VERSION ""

NS_ :

BS_:

BU_: Tank_Sensor2
VAL_TABLE_ FMS_PushButtonStates 1 "On" 0 "Off" ;
VAL_TABLE_ FMS_SSM 3 "Failure Warning " 2 "Functional Test" 1 "NCD" 0 "Normal Operation " ;
VAL_TABLE_ FMS_SDI 2 "Computer 2" 1 "Computer 1" ;
VAL_TABLE_ FMS_Pump_States 1 "Off" 0 "Energized" ;
VAL_TABLE_ vt_BNRaccuracy 1 "Degraded Accuracy" 0 "Nominal Accuracy" ;
VAL_TABLE_ vt_BCDstatus_above_below 3 "Below" 2 "FT (functional test)" 1 "NCD (no computed data)" 0 "Above" ;
VAL_TABLE_ vt_BCDstatus_to_from 3 "From" 2 "FT (functional test)" 1 "NCD (no computed data)" 0 "To" ;
VAL_TABLE_ vt_BCDstatus_right_left 3 "Left" 2 "FT (functional test)" 1 "NCD (no computed data)" 0 "Right" ;
VAL_TABLE_ vt_BCDstatus_east_west 3 "West" 2 "FT (functional test)" 1 "NCD (no computed data)" 0 "East" ;
VAL_TABLE_ vt_BCDstatus_north_south 3 "South" 2 "FT (functional test)" 1 "NCD (no computed data)" 0 "North" ;
VAL_TABLE_ vt_BCDstatus_plus_minus 3 "Minus" 2 "FT (functional test)" 1 "NCD (no computed data)" 0 "Plus" ;
VAL_TABLE_ vt_DSCstatus 3 "FW (failure warning)" 2 "FT (functional test)" 1 "NCD (no computed data)" 0 "NO (normal operation)" ;
VAL_TABLE_ vt_BNRsign_above_below 1 "Below" 0 "Above" ;
VAL_TABLE_ vt_BNRsign_to_from 1 "From" 0 "To" ;
VAL_TABLE_ vt_BNRsign_right_left 1 "Left" 0 "Right" ;
VAL_TABLE_ vt_BNRsign_east_west 1 "West" 0 "East" ;
VAL_TABLE_ vt_BNRsign_north_south 1 "South" 0 "North" ;
VAL_TABLE_ vt_BNRsign_plus_minus 1 "Minus" 0 "Plus" ;
VAL_TABLE_ vt_BNRstatus 3 "NO (normal operation)" 2 "FT (functional test)" 1 "NCD (no computed data)" 0 "FW (failure warning)" ;

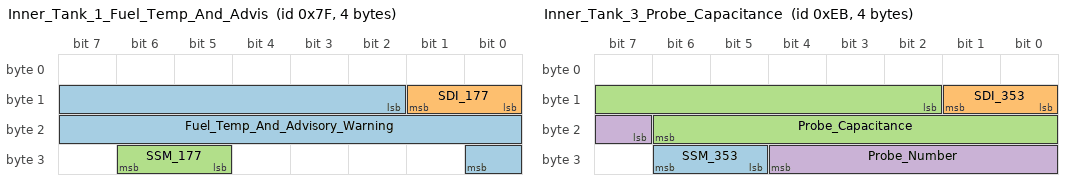
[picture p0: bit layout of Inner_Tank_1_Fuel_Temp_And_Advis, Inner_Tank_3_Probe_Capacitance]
BO_ 127 Inner_Tank_1_Fuel_Temp_And_Advis: 4 Tank_Sensor2
 SG_ Fuel_Temp_And_Advisory_Warning : 10|15@1- (0.25,0) [-512|512] "" Vector__XXX
 SG_ SDI_177 : 8|2@1+ (1,0) [0|3] "" Vector__XXX
 SG_ SSM_177 : 29|2@1+ (1,0) [0|3] "" Vector__XXX

BO_ 235 Inner_Tank_3_Probe_Capacitance: 4 Tank_Sensor2
 SG_ SSM_353 : 29|2@1+ (1,0) [0|3] "" Vector__XXX
 SG_ SDI_353 : 8|2@1+ (1,0) [0|3] "" Vector__XXX
 SG_ Probe_Capacitance : 10|13@1- (1,0) [0|400] "" Vector__XXX
 SG_ Probe_Number : 23|6@1- (1,0) [0|30] "" Vector__XXX

CM_ SG_ 127 SDI_177 "Source/Destination Identifier";
CM_ SG_ 235 SDI_353 "Source/Destination Identifier";
BA_DEF_  "ProtocolType" STRING ;
BA_DEF_ BO_  "A429SpecSource" ENUM  "ARINC","GAMA","Private";
BA_DEF_ BO_  "A429Protocol" ENUM  "BC","AIM","A619","WB1","WB2","WB3";
BA_DEF_ SG_  "A429SignalType" ENUM  "none","BCD","BNR","DISCRETE","ISO-5","SSM","SDI";
BA_DEF_  "A429Parity" ENUM  "unknown","odd","even";
BA_DEF_ BO_  "A429CycleMax" INT 0 0;
BA_DEF_ BO_  "A429Cycle" INT 0 0;
BA_DEF_ BO_  "A429CycleMin" INT 0 0;
BA_DEF_ BU_  "A429Equipment" STRING ;
BA_DEF_  "Baudrate" INT 10500 110000;
BA_DEF_  "ToolName" STRING ;
BA_DEF_  "ToolVersion" STRING ;
BA_DEF_  "Manufacturer" STRING ;
BA_DEF_  "VersionDay" INT 0 31;
BA_DEF_  "VersionMonth" INT 0 12;
BA_DEF_  "VersionWeek" INT 0 0;
BA_DEF_  "BusType" STRING ;
BA_DEF_ BO_  "SystemMessageLongSymbol" STRING ;
BA_DEF_DEF_  "ProtocolType" "Aerospace";
BA_DEF_DEF_  "A429SpecSource" "ARINC";
BA_DEF_DEF_  "A429Protocol" "BC";
BA_DEF_DEF_  "A429SignalType" "BNR";
BA_DEF_DEF_  "A429Parity" "odd";
BA_DEF_DEF_  "A429CycleMax" 0;
BA_DEF_DEF_  "A429Cycle" 0;
BA_DEF_DEF_  "A429CycleMin" 0;
BA_DEF_DEF_  "A429Equipment" "<unknown>";
BA_DEF_DEF_  "Baudrate" 100000;
BA_DEF_DEF_  "ToolName" "manually";
BA_DEF_DEF_  "ToolVersion" "x.y.z.n";
BA_DEF_DEF_  "Manufacturer" "<unknown>";
BA_DEF_DEF_  "VersionDay" 1;
BA_DEF_DEF_  "VersionMonth" 1;
BA_DEF_DEF_  "VersionWeek" 1;
BA_DEF_DEF_  "BusType" "ARINC429";
BA_DEF_DEF_  "SystemMessageLongSymbol" "";
BA_ "A429Equipment" BU_ Tank_Sensor2 "114";
BA_ "A429CycleMax" BO_ 127 100000;
BA_ "A429Cycle" BO_ 127 250000;
BA_ "A429CycleMin" BO_ 127 400000;
BA_ "SystemMessageLongSymbol" BO_ 127 "Inner_Tank_1_Fuel_Temp_And_Advisory_Warning";
BA_ "A429CycleMax" BO_ 235 400000;
BA_ "A429Cycle" BO_ 235 250000;
BA_ "A429CycleMin" BO_ 235 100000;
VAL_ 127 SSM_177 3 "Failure Warning " 2 "Functional Test" 1 "NCD" 0 "Normal Operation " ;
VAL_ 235 SSM_353 3 "Failure Warning " 2 "Functional Test" 1 "NCD" 0 "Normal Operation " ;
SIG_VALTYPE_ 235 Probe_Capacitance : 2;
SIG_VALTYPE_ 235 Probe_Number : 2;
